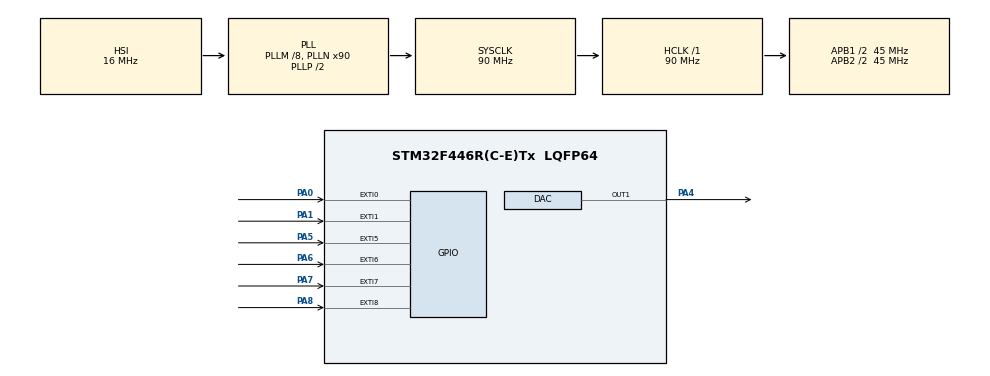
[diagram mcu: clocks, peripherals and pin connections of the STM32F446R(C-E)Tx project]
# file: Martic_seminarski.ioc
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DAC.DAC_Trigger=DAC_TRIGGER_T6_TRGO
Mcu.Family=STM32F4
Mcu.Name=STM32F446R(C-E)Tx
Mcu.Package=LQFP64
NVIC.EXTI0_IRQn=true\:0\:0\:false\:true\:true\:1\:true\:true\:true
NVIC.EXTI1_IRQn=true\:0\:0\:false\:true\:true\:2\:true\:true\:true
NVIC.EXTI9_5_IRQn=true\:0\:0\:false\:true\:true\:3\:true\:true\:true
NVIC.PriorityGroup=NVIC_PRIORITYGROUP_4
NVIC.TIM6_DAC_IRQn=true\:0\:0\:false\:true\:true\:4\:true\:true\:true
PA0-WKUP.GPIO_ModeDefaultEXTI=GPIO_MODE_IT_FALLING
PA0-WKUP.GPIO_PuPd=GPIO_PULLUP
PA0-WKUP.Signal=GPXTI0
PA1.GPIO_ModeDefaultEXTI=GPIO_MODE_IT_FALLING
PA1.GPIO_PuPd=GPIO_PULLUP
PA1.Signal=GPXTI1
PA13.Mode=Serial_Wire
PA13.Signal=SYS_JTMS-SWDIO
PA14.Mode=Serial_Wire
PA14.Signal=SYS_JTCK-SWCLK
PA4.Signal=COMP_DAC1_group
PA5.GPIO_ModeDefaultEXTI=GPIO_MODE_IT_FALLING
PA5.GPIO_PuPd=GPIO_PULLUP
PA5.Signal=GPXTI5
PA6.GPIO_ModeDefaultEXTI=GPIO_MODE_IT_FALLING
PA6.GPIO_PuPd=GPIO_PULLUP
PA6.Signal=GPXTI6
PA7.GPIO_ModeDefaultEXTI=GPIO_MODE_IT_FALLING
PA7.GPIO_PuPd=GPIO_PULLUP
PA7.Signal=GPXTI7
PA8.GPIO_ModeDefaultEXTI=GPIO_MODE_IT_FALLING
PA8.GPIO_PuPd=GPIO_PULLUP
PA8.Signal=GPXTI8
ProjectManager.HeapSize=0x200
ProjectManager.StackSize=0x400
ProjectManager.TargetToolchain=STM32CubeIDE
RCC.AHBFreq_Value=90000000
RCC.APB1CLKDivider=RCC_HCLK_DIV2
RCC.APB1Freq_Value=45000000
RCC.APB1TimFreq_Value=90000000
RCC.APB2CLKDivider=RCC_HCLK_DIV2
RCC.APB2Freq_Value=45000000
RCC.APB2TimFreq_Value=90000000
RCC.CortexFreq_Value=90000000
RCC.HCLKFreq_Value=90000000
RCC.PLLM=8
RCC.PLLN=90
RCC.SYSCLKFreq_VALUE=90000000
RCC.SYSCLKSource=RCC_SYSCLKSOURCE_PLLCLK
RCC.USBFreq_Value=90000000
RCC.VCOOutputFreq_Value=180000000
SH.COMP_DAC1_group.0=DAC_OUT1,DAC_OUT1
TIM6.Period=124
TIM6.Prescaler=89
TIM6.TIM_MasterOutputTrigger=TIM_TRGO_UPDATE
VP_TIM6_VS_ClockSourceINT.Mode=Enable_Timer
board=custom

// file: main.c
/* USER CODE BEGIN Header */
/**
  ******************************************************************************
  * @file           : main.c
  * @brief          : Main program body
  ******************************************************************************
  * @attention
  *
  * Copyright (c) 2025 STMicroelectronics.
  * All rights reserved.
  *
  * This software is licensed under terms that can be found in the LICENSE file
  * in the root directory of this software component.
  * If no LICENSE file comes with this software, it is provided AS-IS.
  *
  ******************************************************************************
  */
/* USER CODE END Header */
#include "main.h"
#include "dac.h"
#include "tim.h"
#include "gpio.h"

/* USER CODE BEGIN PV */
uint8_t wave_index = 0;
uint8_t note_active = 0;

const uint8_t sine_wave[32] = {
  128, 152, 176, 198, 218, 234, 246, 254,
  255, 254, 246, 234, 218, 198, 176, 152,
  128, 104, 80,  58,  38,  22,  10,  2,
  0,   2,  10,  22,  38,  58,  80,  104
};

/* USER CODE END PV */

void SystemClock_Config(void);
static void MX_NVIC_Init(void);

int main(void)
{

  /* MCU Configuration--------------------------------------------------------*/

  /* Reset of all peripherals, Initializes the Flash interface and the Systick. */
  HAL_Init();

  /* Configure the system clock */
  SystemClock_Config();

  /* Initialize all configured peripherals */
  MX_GPIO_Init();
  MX_DAC_Init();
  MX_TIM6_Init();

  /* Initialize interrupts */
  MX_NVIC_Init();
  /* USER CODE BEGIN 2 */
  HAL_DAC_Start(&hdac, DAC_CHANNEL_1);
  HAL_TIM_Base_Start_IT(&htim6);

  /* USER CODE END 2 */

  /* Infinite loop */
  while (1)
  {

	    if (HAL_GPIO_ReadPin(GPIOA, GPIO_PIN_0) == GPIO_PIN_RESET) {  // tipka pritisnuta (aktivna na GND)
	      __HAL_TIM_SET_AUTORELOAD(&htim6, 120);  // C4
	      note_active = 1;
	    } else if (HAL_GPIO_ReadPin(GPIOA, GPIO_PIN_1) == GPIO_PIN_RESET) {
	      __HAL_TIM_SET_AUTORELOAD(&htim6, 107);  // D4
	      note_active = 1;
	    } else if (HAL_GPIO_ReadPin(GPIOA, GPIO_PIN_7) == GPIO_PIN_RESET) {
	      __HAL_TIM_SET_AUTORELOAD(&htim6, 95);   // E4
	      note_active = 1;
	    } else if (HAL_GPIO_ReadPin(GPIOA, GPIO_PIN_8) == GPIO_PIN_RESET) {
	      __HAL_TIM_SET_AUTORELOAD(&htim6, 89);   // F4
	      note_active = 1;
	    } else if (HAL_GPIO_ReadPin(GPIOA, GPIO_PIN_5) == GPIO_PIN_RESET) {
	      __HAL_TIM_SET_AUTORELOAD(&htim6, 80);   // G4
	      note_active = 1;
	    } else if (HAL_GPIO_ReadPin(GPIOA, GPIO_PIN_6) == GPIO_PIN_RESET) {
	      __HAL_TIM_SET_AUTORELOAD(&htim6, 71);   // A4
	      note_active = 1;
	    } else {
	      note_active = 0;  // nema pritisnute tipke, pauza
	    }

	    HAL_Delay(10);  // debounce i rasterećenje CPU-a

  }
}

void SystemClock_Config(void)
{
  RCC_OscInitTypeDef RCC_OscInitStruct = {0};
  RCC_ClkInitTypeDef RCC_ClkInitStruct = {0};

  /** Configure the main internal regulator output voltage
  */
  __HAL_RCC_PWR_CLK_ENABLE();
  __HAL_PWR_VOLTAGESCALING_CONFIG(PWR_REGULATOR_VOLTAGE_SCALE3);

  /** Initializes the RCC Oscillators according to the specified parameters
  * in the RCC_OscInitTypeDef structure.
  */
  RCC_OscInitStruct.OscillatorType = RCC_OSCILLATORTYPE_HSI;
  RCC_OscInitStruct.HSIState = RCC_HSI_ON;
  RCC_OscInitStruct.HSICalibrationValue = RCC_HSICALIBRATION_DEFAULT;
  RCC_OscInitStruct.PLL.PLLState = RCC_PLL_ON;
  RCC_OscInitStruct.PLL.PLLSource = RCC_PLLSOURCE_HSI;
  RCC_OscInitStruct.PLL.PLLM = 8;
  RCC_OscInitStruct.PLL.PLLN = 90;
  RCC_OscInitStruct.PLL.PLLP = RCC_PLLP_DIV2;
  RCC_OscInitStruct.PLL.PLLQ = 2;
  RCC_OscInitStruct.PLL.PLLR = 2;
  if (HAL_RCC_OscConfig(&RCC_OscInitStruct) != HAL_OK)
  {
    Error_Handler();
  }

  /** Initializes the CPU, AHB and APB buses clocks
  */
  RCC_ClkInitStruct.ClockType = RCC_CLOCKTYPE_HCLK|RCC_CLOCKTYPE_SYSCLK
                              |RCC_CLOCKTYPE_PCLK1|RCC_CLOCKTYPE_PCLK2;
  RCC_ClkInitStruct.SYSCLKSource = RCC_SYSCLKSOURCE_PLLCLK;
  RCC_ClkInitStruct.AHBCLKDivider = RCC_SYSCLK_DIV1;
  RCC_ClkInitStruct.APB1CLKDivider = RCC_HCLK_DIV2;
  RCC_ClkInitStruct.APB2CLKDivider = RCC_HCLK_DIV2;

  if (HAL_RCC_ClockConfig(&RCC_ClkInitStruct, FLASH_LATENCY_2) != HAL_OK)
  {
    Error_Handler();
  }
}

/**
  * @brief NVIC Configuration.
  * @retval None
  */
static void MX_NVIC_Init(void)
{
  /* EXTI0_IRQn interrupt configuration */
  HAL_NVIC_SetPriority(EXTI0_IRQn, 0, 0);
  HAL_NVIC_EnableIRQ(EXTI0_IRQn);
  /* EXTI1_IRQn interrupt configuration */
  HAL_NVIC_SetPriority(EXTI1_IRQn, 0, 0);
  HAL_NVIC_EnableIRQ(EXTI1_IRQn);
  /* EXTI9_5_IRQn interrupt configuration */
  HAL_NVIC_SetPriority(EXTI9_5_IRQn, 0, 0);
  HAL_NVIC_EnableIRQ(EXTI9_5_IRQn);
  /* TIM6_DAC_IRQn interrupt configuration */
  HAL_NVIC_SetPriority(TIM6_DAC_IRQn, 0, 0);
  HAL_NVIC_EnableIRQ(TIM6_DAC_IRQn);
}

/* USER CODE BEGIN 4 */

void HAL_TIM_PeriodElapsedCallback(TIM_HandleTypeDef *htim)
{
  if (htim->Instance == TIM6 && note_active)
  {
    HAL_DAC_SetValue(&hdac, DAC_CHANNEL_1, DAC_ALIGN_8B_R, sine_wave[wave_index++]);
    if (wave_index >= sizeof(sine_wave)) wave_index = 0;
  }
}

/* USER CODE END 4 */

void Error_Handler(void)
{
  __disable_irq();
  while (1)
  {
  }
}
